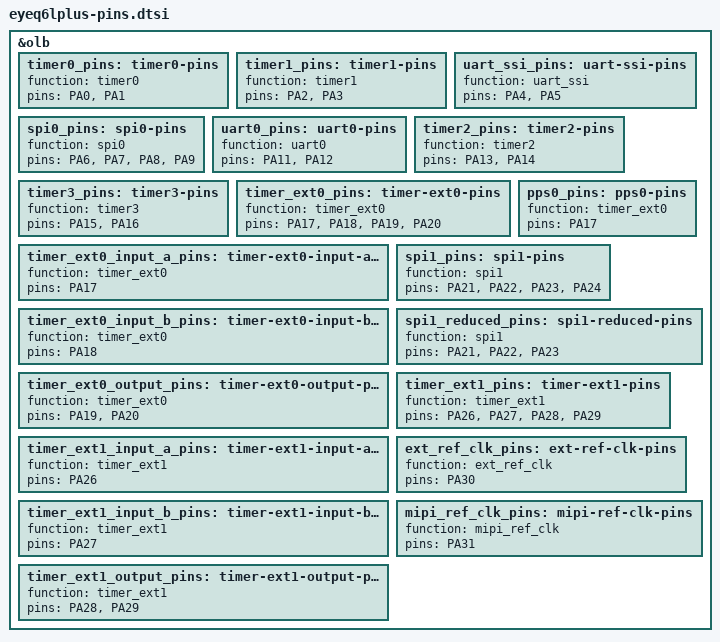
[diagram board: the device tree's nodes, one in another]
// SPDX-License-Identifier: (GPL-2.0-only OR BSD-2-Clause)

&olb {
	timer0_pins: timer0-pins {
		function = "timer0";
		pins = "PA0", "PA1";
	};
	timer1_pins: timer1-pins {
		function = "timer1";
		pins = "PA2", "PA3";
	};
	uart_ssi_pins: uart-ssi-pins {
		function = "uart_ssi";
		pins = "PA4", "PA5";
	};
	spi0_pins: spi0-pins {
		function = "spi0";
		pins = "PA6", "PA7", "PA8", "PA9";
	};
	uart0_pins: uart0-pins {
		function = "uart0";
		pins = "PA11", "PA12";
	};
	timer2_pins: timer2-pins {
		function = "timer2";
		pins = "PA13", "PA14";
	};
	timer3_pins: timer3-pins {
		function = "timer3";
		pins = "PA15", "PA16";
	};
	timer_ext0_pins: timer-ext0-pins {
		function = "timer_ext0";
		pins = "PA17", "PA18", "PA19", "PA20";
	};
	timer_ext0_input_a_pins: timer-ext0-input-a-pins {
		function = "timer_ext0";
		pins = "PA17";
	};
	pps0_pins: pps0-pins {
		function = "timer_ext0";
		pins = "PA17";
	};
	timer_ext0_input_b_pins: timer-ext0-input-b-pins {
		function = "timer_ext0";
		pins = "PA18";
	};
	timer_ext0_output_pins: timer-ext0-output-pins {
		function = "timer_ext0";
		pins = "PA19", "PA20";
	};
	spi1_pins: spi1-pins {
		function = "spi1";
		pins = "PA21", "PA22", "PA23", "PA24";
	};
	spi1_reduced_pins: spi1-reduced-pins {
		function = "spi1";
		pins = "PA21", "PA22", "PA23";
	};
	timer_ext1_pins: timer-ext1-pins {
		function = "timer_ext1";
		pins = "PA26", "PA27", "PA28", "PA29";
	};
	timer_ext1_input_a_pins: timer-ext1-input-a-pins {
		function = "timer_ext1";
		pins = "PA26";
	};
	timer_ext1_input_b_pins: timer-ext1-input-b-pins {
		function = "timer_ext1";
		pins = "PA27";
	};
	timer_ext1_output_pins: timer-ext1-output-pins {
		function = "timer_ext1";
		pins = "PA28", "PA29";
	};
	ext_ref_clk_pins: ext-ref-clk-pins {
		function = "ext_ref_clk";
		pins = "PA30";
	};
	mipi_ref_clk_pins: mipi-ref-clk-pins {
		function = "mipi_ref_clk";
		pins = "PA31";
	};
};
